# STMP3770 register map
Vendor: Freescale Semiconductor (NXP); Series: STMP37xx; File version: 1.0
CPU: other r0p0, little endian, no MPU, no FPU, 2 interrupt priority bits
Registers are 32-bit, read-write, reset 0x0 unless marked. A register's access mark holds for its fields unless they carry their own. Offsets are from the block's base; [hi:lo] are bit positions.

## DRI — 数字无线电接口(DRI,串行调试/数据接口)
Base 0x80074000
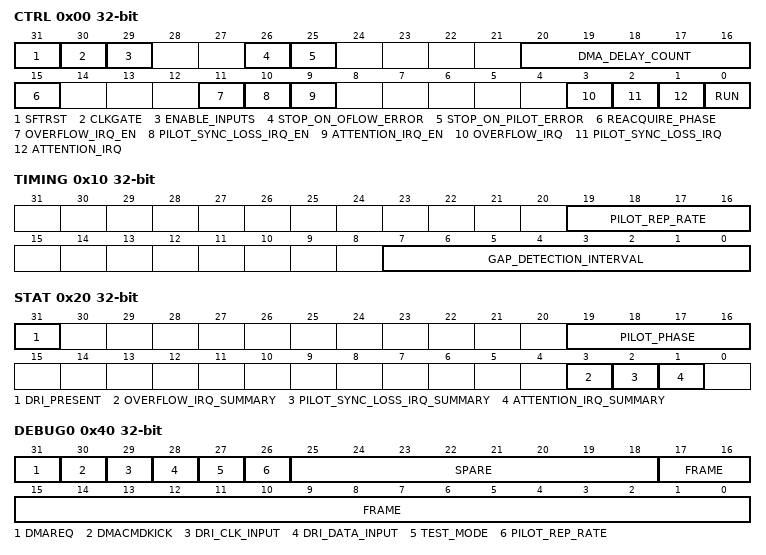
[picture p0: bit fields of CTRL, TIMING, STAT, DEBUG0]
0x00 CTRL — DRI Control Register
  [31] SFTRST — Soft reset. 0=RUN (normal operation), 1=RESET (hold in reset). Default 0x1.
    0=RUN; 1=RESET
  [30] CLKGATE — Clock gate. 0=RUN (normal), 1=NO_CLKS (gate clocks). Default 0x1.
    0=RUN; 1=NO_CLKS
  [29] ENABLE_INPUTS — Enable input pads in digital mode instead of analog line-in. 0=ANALOG_LINE_IN, 1=DRI_DIGITAL_IN. Default 0x0.
    0=ANALOG_LINE_IN; 1=DRI_DIGITAL_IN
  [26] STOP_ON_OFLOW_ERROR — Stop DMA on overflow. 0=IGNORE (keep transferring), 1=STOP. Default 0x0.
    0=IGNORE; 1=STOP
  [25] STOP_ON_PILOT_ERROR — Stop DMA on loss of pilot sync. 0=IGNORE, 1=STOP. Default 0x0.
    0=IGNORE; 1=STOP
  [20:16] DMA_DELAY_COUNT — Spare bits (formerly encoded DMA request idle cycle count). Default 0x01.
  [15] REACQUIRE_PHASE — Reacquire phase alignment with pilot peak marker. HW clears when next pilot peak received. 0=NORMAL, 1=NEW_PHASE. Default 0x0.
    0=NORMAL; 1=NEW_PHASE
  [11] OVERFLOW_IRQ_EN — Overflow interrupt enable. 0=DISABLED, 1=ENABLED. Default 0x0.
    0=DISABLED; 1=ENABLED
  [10] PILOT_SYNC_LOSS_IRQ_EN — Pilot sync loss interrupt enable. 0=DISABLED, 1=ENABLED. Default 0x0.
    0=DISABLED; 1=ENABLED
  [9] ATTENTION_IRQ_EN — Attention interrupt enable. 0=DISABLED, 1=ENABLED. Default 0x0.
    0=DISABLED; 1=ENABLED
  [3] OVERFLOW_IRQ — Overflow interrupt pending. DMA FIFO overrun detected. Write 1 to SET/CLR address to clear. 0=NO_REQUEST, 1=REQUEST. Default 0x0.
    0=NO_REQUEST; 1=REQUEST
  [2] PILOT_SYNC_LOSS_IRQ — Pilot sync loss interrupt pending. Pilot peak not seen at expected 8-sample boundary. Write 1 to SET/CLR to clear. 0=NO_REQUEST, 1=REQUEST. Default 0x0.
    0=NO_REQUEST; 1=REQUEST
  [1] ATTENTION_IRQ — Attention interrupt pending. Attention bit detected in DRI frame. Write 1 to SET/CLR to clear. 0=NO_REQUEST, 1=REQUEST. Default 0x0.
    0=NO_REQUEST; 1=REQUEST
  [0] RUN — Enable DRI controller operation. Auto-set by DMA commands; can be set by SW for soft DMA. 0=HALT, 1=RUN. Default 0x0.
    0=HALT; 1=RUN
0x10 TIMING — DRI Timing Register
  [19:16] PILOT_REP_RATE — Number of DRI samples between pilot sample centers. Default 0x8.
  [7:0] GAP_DETECTION_INTERVAL — Number of 24-MHz crystal clocks to count to detect a gap in DRI source clocks. Default 0x10.
0x20 STAT — DRI Status Register
  [31] DRI_PRESENT — DRI presence indicator. 0=UNAVAILABLE (DRI not present), 1=AVAILABLE (DRI present). Default 0x1.
    0=UNAVAILABLE; 1=AVAILABLE
  [19:16] PILOT_PHASE — Phase of the last pilot peak marker relative to phase established when DRI exited soft reset. 0 until first phase error. Default 0x0.
  [3] OVERFLOW_IRQ_SUMMARY — Logical AND of OVERFLOW_IRQ status and enable. 0=NO_REQUEST, 1=REQUEST. Default 0x0.
    0=NO_REQUEST; 1=REQUEST
  [2] PILOT_SYNC_LOSS_IRQ_SUMMARY — Logical AND of PILOT_SYNC_LOSS_IRQ status and enable. 0=NO_REQUEST, 1=REQUEST. Default 0x0.
    0=NO_REQUEST; 1=REQUEST
  [1] ATTENTION_IRQ_SUMMARY — Logical AND of ATTENTION_IRQ status and enable. 0=NO_REQUEST, 1=REQUEST. Default 0x0.
    0=NO_REQUEST; 1=REQUEST
0x30 DATA — DRI Controller DMA Read Data Register
  [31:0] DATA — DMA read/write data register backed by an 8-deep FIFO. Default 0x00000000.
0x40 DEBUG0 ro — DRI Device Debug Register 0
  [31] DMAREQ — Read-only view of DMA request line toggle state. Default 0x0.
  [30] DMACMDKICK — Read-only view of DMA command kick toggle state. Default 0x0.
  [29] DRI_CLK_INPUT — Read-only view of DRI clock input signal from analog logic. Default 0x0.
  [28] DRI_DATA_INPUT — Read-only view of DRI data input signal from analog logic. Default 0x0.
  [27] TEST_MODE — Enable internal test mode (pseudo DRI frames). Integrated test source removed; now a spare bit. Default 0x0.
  [26] PILOT_REP_RATE — Test mode pilot repeat rate select. 0=8_AT_4MHZ, 1=12_AT_6MHZ. Integrated test source removed; now a spare bit. Default 0x0.
    0=_8_AT_4MHZ; 1=_12_AT_6MHZ
  [25:18] SPARE — Spare bits for patching hardware in metal. Default 0x00.
  [17:0] FRAME — Current state of frame synchronizing register received from digital radio receiver. Default 0x0000.
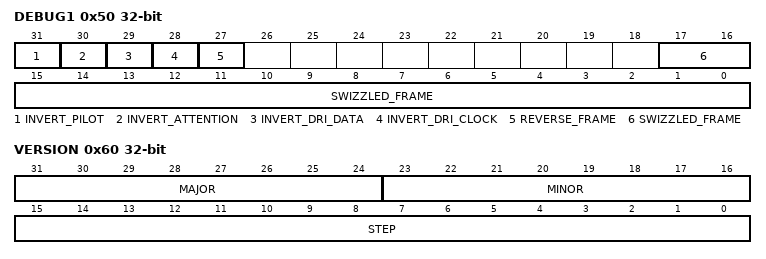
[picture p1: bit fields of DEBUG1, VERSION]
0x50 DEBUG1 ro — DRI Device Debug Register 1
  [31] INVERT_PILOT — Invert frame register bit used for pilot peak indicator. 0=NORMAL, 1=INVERTED. Default 0x0.
    0=NORMAL; 1=INVERTED
  [30] INVERT_ATTENTION — Invert frame register bit used for attention bit. 0=NORMAL, 1=INVERTED. Default 0x0.
    0=NORMAL; 1=INVERTED
  [29] INVERT_DRI_DATA — Invert DRI_DATA prior to shifting into shift register. 0=NORMAL, 1=INVERTED. Default 0x0.
    0=NORMAL; 1=INVERTED
  [28] INVERT_DRI_CLOCK — Invert DRI_CLK edge used to shift data into shift register. 0=NORMAL, 1=INVERTED. Default 0x0.
    0=NORMAL; 1=INVERTED
  [27] REVERSE_FRAME — Reverse bit order of 18-bit frames from digital radio. 0=NORMAL, 1=REVERSED. Default 0x0.
    0=NORMAL; 1=REVERSED
  [17:0] SWIZZLED_FRAME — Current frame register as swizzled by invert/reverse bits in DEBUG1. Default 0x0000.
0x60 VERSION ro — DRI Version Register
  [31:24] MAJOR — Major field of RTL version. Fixed read-only. Default 0x01.
  [23:16] MINOR — Minor field of RTL version. Fixed read-only. Default 0x01.
  [15:0] STEP — Stepping of RTL version. Fixed read-only. Default 0x0000.
